# cyt4dn register map
Vendor: Cypress Semiconductor; Series: cyt4dn; File version: 1.0
CPU: CM7 r0p1, little endian, MPU, FPU, VTOR, 3 interrupt priority bits
Registers are 32-bit, read-write, reset 0x0 unless marked. A register's access mark holds for its fields unless they carry their own. Offsets are from the block's base; [hi:lo] are bit positions; lines under a group give offsets from that group; {n}, {i} and the like mark numbered series; 'fields as' and 'values as' point back to an identical list.

## VIDEOSS0 (part 1 of 18) — Video and Graphics Subsystem
Base 0x40A00000
0x00 SUBSS group — Sub Interface
  0x00 VIDEOSSCFG group — Subsystem Control.
    0x00 IPCTRL — IP Control Register
      [31] CTLENABLED — VIDEOSS enable/disable bit.
        0=DIS (Disable the entire VIDEOSS. System will be held in reset until re-enabled (with the exception of the AHB interface and this register)); 1=EN (Enable VIDEOSS)
    0x04 IPCTRLGFX2D reset 0x80000000 — IP Control Register for Graphics 2D Core
      [31] CTLENABLED_GFX2D
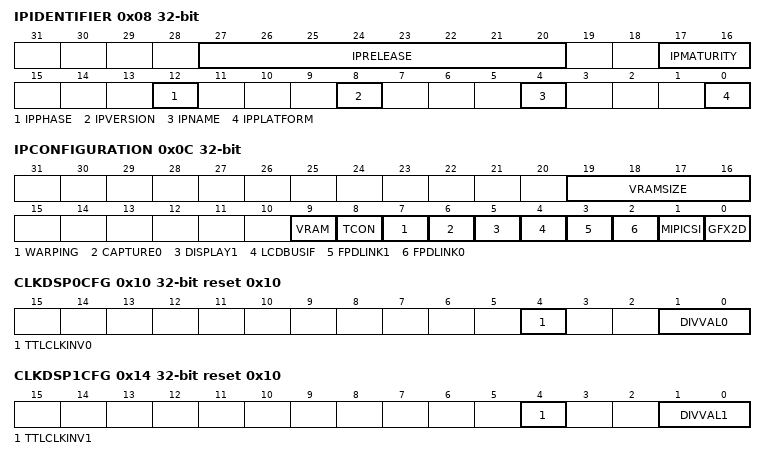
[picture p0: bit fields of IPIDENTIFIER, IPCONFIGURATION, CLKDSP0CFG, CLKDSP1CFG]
    0x08 IPIDENTIFIER ro reset not defined — IP and Design Release Identification
      [27:20] IPRELEASE — Design Release ID
      [17:16] IPMATURITY — CIC Chip Integration Cycle
        0=NONE (Pre Review); 1=CPR (CIC Physical Readiness Review); 2=CMR (CIC Mock Review); 3=CFR (CIC Final Handoff Review)
      [12] IPPHASE — IP Vault Phase
      [8] IPVERSION — IP Vault Version
      [4] IPNAME — Name of IP
        0=VIDEOSS (Video and Graphics Subsystem)
      [0] IPPLATFORM — Name of SOC Platform
        0=MXS40_S40E (MXS40 High Temperature Variant)
    0x0C IPCONFIGURATION ro reset not defined — IP Design Configuration
      [19:16] VRAMSIZE — Size of embedded Video RAM if available (in MB).
      [9] VRAM — Embedded Video RAM available (0 = no, 1 = yes)
      [8] TCON — Timing Controller available in Display Engine (0 = no, 1 = yes)
      [7] WARPING — Warping Layer available in Composition Engine (0 = no, 1 = yes)
      [6] CAPTURE0 — Capture Engine available (0 = no, 1 = yes)
      [5] DISPLAY1 — 2nd Display Engine available (0 = no, 1 = yes)
      [4] LCDBUSIF — LCD Bus Output Interface available (0 = no, 1 = yes)
      [3] FPDLINK1 — 2nd FPD-Link Video Output Interface available (0 = no, 1 = yes)
      [2] FPDLINK0 — 1st FPD-Link Video Output Interface available (0 = no, 1 = yes)
      [1] MIPICSI — MIPI CSI-2 Video Input Interface available (0 = no, 1 = yes)
      [0] GFX2D — Graphics 2D Core available (0 = no, 1 = yes)
    0x10 CLKDSP0CFG reset 0x10 — Display 0 Clock Configuration Register
      [4] TTLCLKINV0 — Enable bit for pixel clock inversion on TTL display output interface 0. If enabled, pixel data changes with falling instead of rising clock edge (180 deg phase shift).
      [1:0] DIVVAL0 — Clock Divider Setting (KDIV)
        0=DIV1 (No division); 1=DIV2 (Divide by 2); 2=DIV4 (Divide by 4); 3=DIV8 (Divide by 8)
    0x14 CLKDSP1CFG reset 0x10 — Display 1 Clock Configuration Register
      [4] TTLCLKINV1 — Enable bit for pixel clock inversion on TTL display output interface 1. If enabled, pixel data changes with falling instead of rising clock edge (180 deg phase shift).
      [1:0] DIVVAL1 — Clock Divider Setting (KDIV)
        values as SUBSS.VIDEOSSCFG.CLKDSP0CFG.DIVVAL0
    0x18 CAP0CFG — Capture 0 Confifuration
      [1:0] CAP0SRC — Capture Source Selection
        0=TTL (TTL0 interface selected); 1=CSI (CSI-2 (DPHY) Interface Selected); 2=DSP0 (N/A); 3=DSP1 (N/A)
    0x1C FPDLINKCFG — FPDLink Configuration
      [0] FPDLINKSEL — Selects the channel mode for the two FDP-link interfaces.
        0=SINGLE (FPD-link 0 and 1 are operating independently, driven by the two Display Engine 0 and 1.); 1=DUAL (FPD-link 0 and 1 are operating synchronously, both driven by Display Engine 0.)
  0x400 VRAM group — Video RAM.
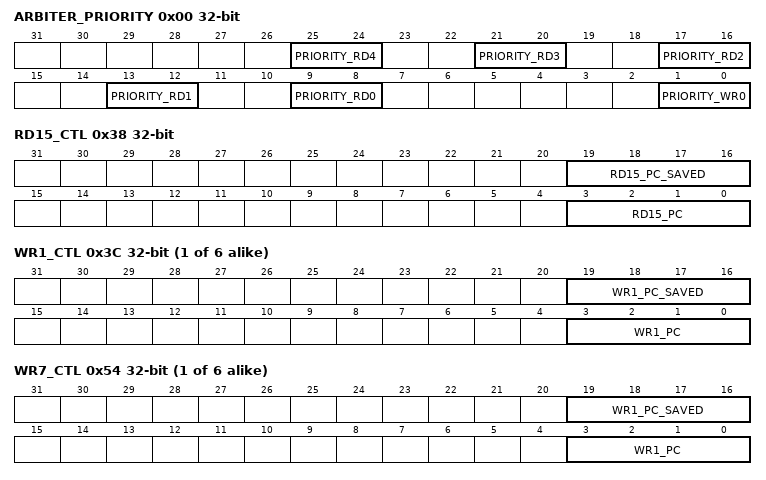
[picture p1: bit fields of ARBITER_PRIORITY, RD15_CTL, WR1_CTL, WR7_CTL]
    0x00 ARBITER_PRIORITY
      [4n+9:4n+8] PRIORITY_RD{n} (n=0..4) — Priority for read slave interface {n}.
      [1:0] PRIORITY_WR0 — Priority for write slave interfaces 0.
  0x10000 INFRA group — Bus Infrastructure.
    0x00 GFX_MPU group — MPU configuration.
      0x00 RD1_CTL — Memory protection context for AXI read master with ID=1
        [19:16] RD1_PC_SAVED — Saved protection context. Modifications to this field are constrained by the associated RDx_CTL.PC_MASK_0 and RDx_CTL.PC_MASK_15_TO_1[] fields.
        [3:0] RD1_PC — Active protection context. Modifications to this field are constrained by the associated RDx_CTL.PC_MASK_0 and RDx_CTL.PC_MASK_15_TO_1[] fields.
      0x04 RD2_CTL — Memory protection context for AXI read master with ID=2
        [19:16] RD2_PC_SAVED — Saved protection context. Modifications to this field are constrained by the associated RDx_CTL.PC_MASK_0 and RDx_CTL.PC_MASK_15_TO_1[] fields.
        [3:0] RD2_PC — Active protection context. Modifications to this field are constrained by the associated RDx_CTL.PC_MASK_0 and RDx_CTL.PC_MASK_15_TO_1[] fields.
      0x08 RD3_CTL — Memory protection context for AXI read master with ID=3
        [19:16] RD3_PC_SAVED — Saved protection context. Modifications to this field are constrained by the associated RDx_CTL.PC_MASK_0 and RDx_CTL.PC_MASK_15_TO_1[] fields.
        [3:0] RD3_PC — Active protection context. Modifications to this field are constrained by the associated RDx_CTL.PC_MASK_0 and RDx_CTL.PC_MASK_15_TO_1[] fields.
      0x0C RD4_CTL — Memory protection context for AXI read master with ID=4
        [19:16] RD4_PC_SAVED — Saved protection context. Modifications to this field are constrained by the associated RDx_CTL.PC_MASK_0 and RDx_CTL.PC_MASK_15_TO_1[] fields.
        [3:0] RD4_PC — Active protection context. Modifications to this field are constrained by the associated RDx_CTL.PC_MASK_0 and RDx_CTL.PC_MASK_15_TO_1[] fields.
      0x10 RD5_CTL — Memory protection context for AXI read master with ID=5
        [19:16] RD5_PC_SAVED — Saved protection context. Modifications to this field are constrained by the associated RDx_CTL.PC_MASK_0 and RDx_CTL.PC_MASK_15_TO_1[] fields.
        [3:0] RD5_PC — Active protection context. Modifications to this field are constrained by the associated RDx_CTL.PC_MASK_0 and RDx_CTL.PC_MASK_15_TO_1[] fields.
      0x14 RD6_CTL — Memory protection context for AXI read master with ID=6
        [19:16] RD6_PC_SAVED — Saved protection context. Modifications to this field are constrained by the associated RDx_CTL.PC_MASK_0 and RDx_CTL.PC_MASK_15_TO_1[] fields.
        [3:0] RD6_PC — Active protection context. Modifications to this field are constrained by the associated RDx_CTL.PC_MASK_0 and RDx_CTL.PC_MASK_15_TO_1[] fields.
      0x18 RD7_CTL — Memory protection7context for AXI read master with ID=7
        [19:16] RD7_PC_SAVED — Saved protection context. Modifications to this field are constrained by the associated RDx_CTL.PC_MASK_0 and RDx_CTL.PC_MASK_15_TO_1[] fields.
        [3:0] RD7_PC — Active protection context. Modifications to this field are constrained by the associated RDx_CTL.PC_MASK_0 and RDx_CTL.PC_MASK_15_TO_1[] fields.
      0x1C RD8_CTL — Memory protection7context for AXI read master with ID=8
        [19:16] RD8_PC_SAVED — Saved protection context. Modifications to this field are constrained by the associated RDx_CTL.PC_MASK_0 and RDx_CTL.PC_MASK_15_TO_1[] fields.
        [3:0] RD8_PC — Active protection context. Modifications to this field are constrained by the associated RDx_CTL.PC_MASK_0 and RDx_CTL.PC_MASK_15_TO_1[] fields.
      0x20 RD9_CTL — Memory protection7context for AXI read master with ID=9
        [19:16] RD9_PC_SAVED — Saved protection context. Modifications to this field are constrained by the associated RDx_CTL.PC_MASK_0 and RDx_CTL.PC_MASK_15_TO_1[] fields.
        [3:0] RD9_PC — Active protection context. Modifications to this field are constrained by the associated RDx_CTL.PC_MASK_0 and RDx_CTL.PC_MASK_15_TO_1[] fields.
      0x24 RD10_CTL — Memory protection7context for AXI read master with ID=10
        [19:16] RD10_PC_SAVED — Saved protection context. Modifications to this field are constrained by the associated RDx_CTL.PC_MASK_0 and RDx_CTL.PC_MASK_15_TO_1[] fields.
        [3:0] RD10_PC — Active protection context. Modifications to this field are constrained by the associated RDx_CTL.PC_MASK_0 and RDx_CTL.PC_MASK_15_TO_1[] fields.
      0x28 RD11_CTL — Memory protection7context for AXI read master with ID=11
        [19:16] RD11_PC_SAVED — Saved protection context. Modifications to this field are constrained by the associated RDx_CTL.PC_MASK_0 and RDx_CTL.PC_MASK_15_TO_1[] fields.
        [3:0] RD11_PC — Active protection context. Modifications to this field are constrained by the associated RDx_CTL.PC_MASK_0 and RDx_CTL.PC_MASK_15_TO_1[] fields.
      0x2C RD12_CTL — Memory protection7context for AXI read master with ID=12
        [19:16] RD12_PC_SAVED — Saved protection context. Modifications to this field are constrained by the associated RDx_CTL.PC_MASK_0 and RDx_CTL.PC_MASK_15_TO_1[] fields.
        [3:0] RD12_PC — Active protection context. Modifications to this field are constrained by the associated RDx_CTL.PC_MASK_0 and RDx_CTL.PC_MASK_15_TO_1[] fields.
      0x30 RD13_CTL — Memory protection7context for AXI read master with ID=12
        [19:16] RD13_PC_SAVED — Saved protection context. Modifications to this field are constrained by the associated RDx_CTL.PC_MASK_0 and RDx_CTL.PC_MASK_15_TO_1[] fields.
        [3:0] RD13_PC — Active protection context. Modifications to this field are constrained by the associated RDx_CTL.PC_MASK_0 and RDx_CTL.PC_MASK_15_TO_1[] fields.
      0x34 RD14_CTL — Memory protection7context for AXI read master with ID=12
        [19:16] RD14_PC_SAVED — Saved protection context. Modifications to this field are constrained by the associated RDx_CTL.PC_MASK_0 and RDx_CTL.PC_MASK_15_TO_1[] fields.
        [3:0] RD14_PC — Active protection context. Modifications to this field are constrained by the associated RDx_CTL.PC_MASK_0 and RDx_CTL.PC_MASK_15_TO_1[] fields.
      0x38 RD15_CTL — Memory protection7context for AXI read master with ID=12
        [19:16] RD15_PC_SAVED — Saved protection context. Modifications to this field are constrained by the associated RDx_CTL.PC_MASK_0 and RDx_CTL.PC_MASK_15_TO_1[] fields.
        [3:0] RD15_PC — Active protection context. Modifications to this field are constrained by the associated RDx_CTL.PC_MASK_0 and RDx_CTL.PC_MASK_15_TO_1[] fields.
      {0x38+4l} WR{l}_CTL (l=1..6) — Memory protection context for AXI write master with ID={l}
        [19:16] WR{l}_PC_SAVED — Saved protection context. Modifications to this field are constrained by the associated WRx_CTL.PC_MASK_0 and WRx_CTL.PC_MASK_15_TO_1[] fields.
        [3:0] WR{l}_PC — Active protection context. Modifications to this field are constrained by the associated WRx_CTL.PC_MASK_0 and WRx_CTL.PC_MASK_15_TO_1[] fields.
      {0x38+4l} WR{l}_CTL (l=7..12) — Memory protection7context for AXI write master with ID={l}
        fields as SUBSS.INFRA.GFX_MPU.WR1_CTL
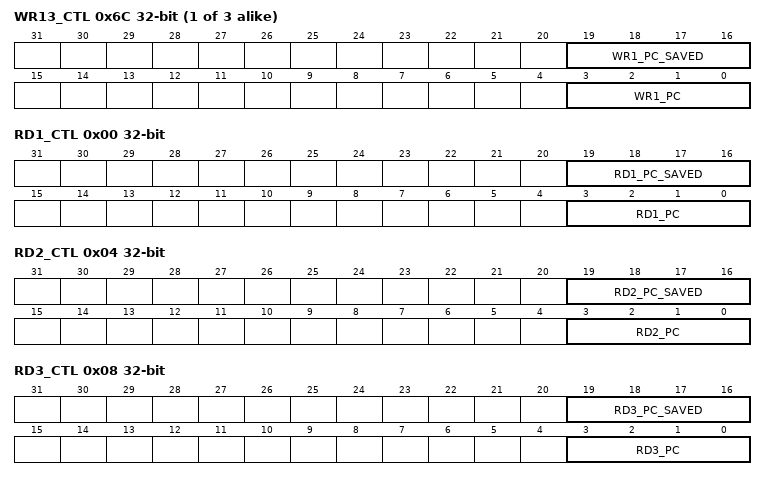
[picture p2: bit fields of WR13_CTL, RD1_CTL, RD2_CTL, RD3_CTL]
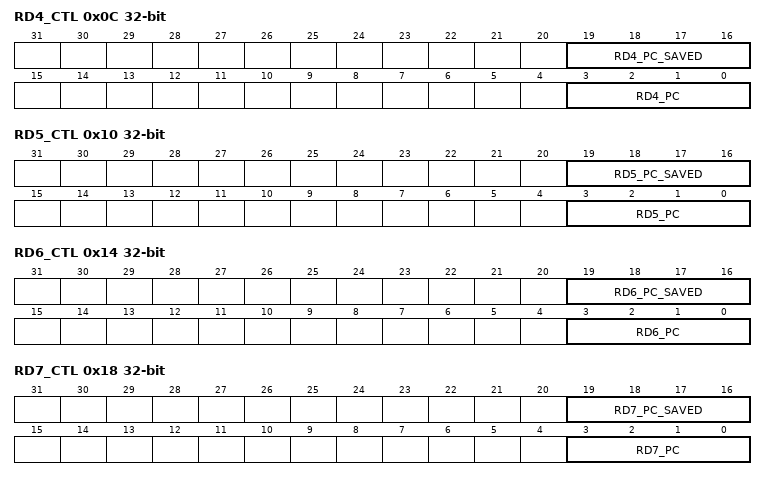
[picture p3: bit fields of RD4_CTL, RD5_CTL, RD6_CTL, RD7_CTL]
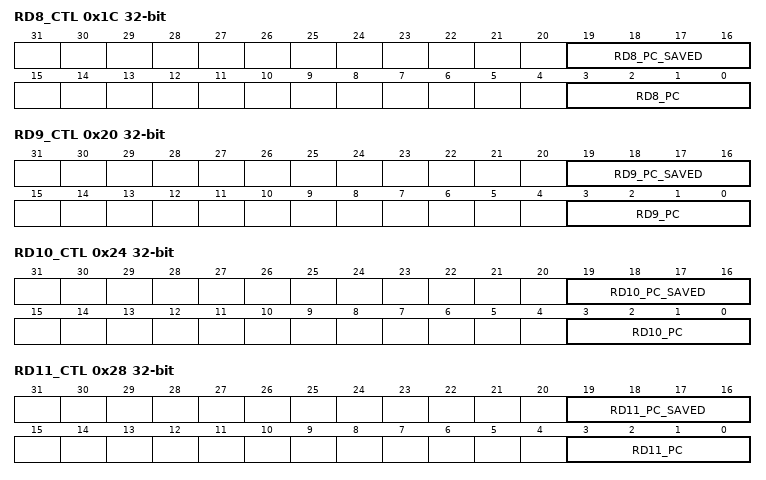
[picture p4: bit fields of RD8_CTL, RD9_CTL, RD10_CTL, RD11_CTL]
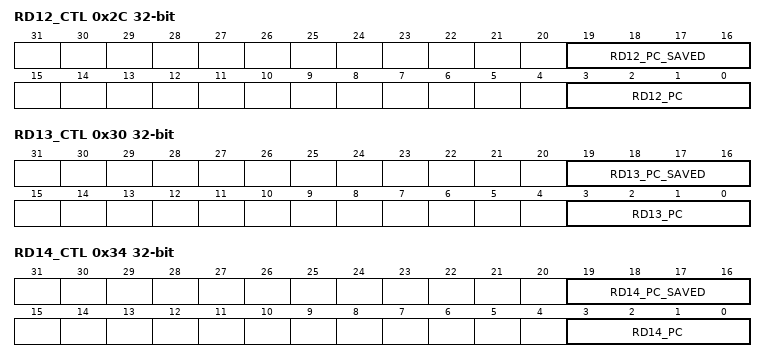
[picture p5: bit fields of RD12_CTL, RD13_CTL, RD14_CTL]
      {0x38+4l} WR{l}_CTL (l=13..15) — Memory protection7context for AXI write master with ID=12
        fields as SUBSS.INFRA.GFX_MPU.WR1_CTL
    0x400 VRPU group — VRPU configuration.
      0x00 RD1_CTL reset 0x303 — VRAM Protection for read master with ID=1
        [31:17] RD1_PC_MASK_15_TO_1 — Protection context mask for protection contexts '15' downto '1'. Bit PC_MASK_15_TO_1[i] indicates if the MPU MS_CTL.PC[3:0] protection context field can be set to the value 'i+1': - PC_MASK_15_TO_1[i] is '0': MPU MS_CTL.PC[3:0] can NOT be set to 'i+1'; and PC[3:0] is not changed. If the protection context of the write transfer is '0', protection is not applied and PC[3:0] can be changed. - PC_MASK_15_TO_1[i] is '1': MPU MS_CTL.PC[3:0] can be set to 'i+1'.
        [16] RD1_PC_MASK_0 ro — Protection context mask for protection context '0'. This field is a constant '0'.
        [9:8] RD1_PRIO — Device wide bus arbitration priority setting ('0': highest priority, '3': lowest priority). Masters with the same priority setting form a 'priority group'. Within a 'priority group', roundrobin arbitration is performed.
        [1] RD1_NS — Security setting ('0': secure mode; '1': non-secure mode).
        [0] RD1_P — Privileged setting ('0': user mode; '1': privileged mode).
      0x04 RD2_CTL reset 0x303 — VRAM Protection for read master with ID=2
        [31:17] RD2_PC_MASK_15_TO_1 — Protection context mask for protection contexts '15' downto '1'. Bit PC_MASK_15_TO_1[i] indicates if the MPU MS_CTL.PC[3:0] protection context field can be set to the value 'i+1': - PC_MASK_15_TO_1[i] is '0': MPU MS_CTL.PC[3:0] can NOT be set to 'i+1'; and PC[3:0] is not changed. If the protection context of the write transfer is '0', protection is not applied and PC[3:0] can be changed. - PC_MASK_15_TO_1[i] is '1': MPU MS_CTL.PC[3:0] can be set to 'i+1'.
        [16] RD2_PC_MASK_0 ro — Protection context mask for protection context '0'. This field is a constant '0'.
        [9:8] RD2_PRIO — Device wide bus arbitration priority setting ('0': highest priority, '3': lowest priority). Masters with the same priority setting form a 'priority group'. Within a 'priority group', roundrobin arbitration is performed.
        [1] RD2_NS — Security setting ('0': secure mode; '1': non-secure mode).
        [0] RD2_P — Privileged setting ('0': user mode; '1': privileged mode).
      0x08 RD3_CTL reset 0x303 — VRAM Protection for read master with ID=3
        [31:17] RD3_PC_MASK_15_TO_1 — Protection context mask for protection contexts '15' downto '1'. Bit PC_MASK_15_TO_1[i] indicates if the MPU MS_CTL.PC[3:0] protection context field can be set to the value 'i+1': - PC_MASK_15_TO_1[i] is '0': MPU MS_CTL.PC[3:0] can NOT be set to 'i+1'; and PC[3:0] is not changed. If the protection context of the write transfer is '0', protection is not applied and PC[3:0] can be changed. - PC_MASK_15_TO_1[i] is '1': MPU MS_CTL.PC[3:0] can be set to 'i+1'.
        [16] RD3_PC_MASK_0 ro — Protection context mask for protection context '0'. This field is a constant '0'.
        [9:8] RD3_PRIO — Device wide bus arbitration priority setting ('0': highest priority, '3': lowest priority). Masters with the same priority setting form a 'priority group'. Within a 'priority group', roundrobin arbitration is performed.
        [1] RD3_NS — Security setting ('0': secure mode; '1': non-secure mode).
        [0] RD3_P — Privileged setting ('0': user mode; '1': privileged mode).
      0x0C RD4_CTL reset 0x303 — VRAM Protection for read master with ID=4
        [31:17] RD4_PC_MASK_15_TO_1 — Protection context mask for protection contexts '15' downto '1'. Bit PC_MASK_15_TO_1[i] indicates if the MPU MS_CTL.PC[3:0] protection context field can be set to the value 'i+1': - PC_MASK_15_TO_1[i] is '0': MPU MS_CTL.PC[3:0] can NOT be set to 'i+1'; and PC[3:0] is not changed. If the protection context of the write transfer is '0', protection is not applied and PC[3:0] can be changed. - PC_MASK_15_TO_1[i] is '1': MPU MS_CTL.PC[3:0] can be set to 'i+1'.
        [16] RD4_PC_MASK_0 ro — Protection context mask for protection context '0'. This field is a constant '0'.
        [9:8] RD4_PRIO — Device wide bus arbitration priority setting ('0': highest priority, '3': lowest priority). Masters with the same priority setting form a 'priority group'. Within a 'priority group', roundrobin arbitration is performed.
        [1] RD4_NS — Security setting ('0': secure mode; '1': non-secure mode).
        [0] RD4_P — Privileged setting ('0': user mode; '1': privileged mode).
      0x10 RD5_CTL reset 0x303 — VRAM Protection for read master with ID=5
        [31:17] RD5_PC_MASK_15_TO_1 — Protection context mask for protection contexts '15' downto '1'. Bit PC_MASK_15_TO_1[i] indicates if the MPU MS_CTL.PC[3:0] protection context field can be set to the value 'i+1': - PC_MASK_15_TO_1[i] is '0': MPU MS_CTL.PC[3:0] can NOT be set to 'i+1'; and PC[3:0] is not changed. If the protection context of the write transfer is '0', protection is not applied and PC[3:0] can be changed. - PC_MASK_15_TO_1[i] is '1': MPU MS_CTL.PC[3:0] can be set to 'i+1'.
        [16] RD5_PC_MASK_0 ro — Protection context mask for protection context '0'. This field is a constant '0'.
        [9:8] RD5_PRIO — Device wide bus arbitration priority setting ('0': highest priority, '3': lowest priority). Masters with the same priority setting form a 'priority group'. Within a 'priority group', roundrobin arbitration is performed.
        [1] RD5_NS — Security setting ('0': secure mode; '1': non-secure mode).
        [0] RD5_P — Privileged setting ('0': user mode; '1': privileged mode).
      0x14 RD6_CTL reset 0x303 — VRAM Protection for read master with ID=6
        [31:17] RD6_PC_MASK_15_TO_1 — Protection context mask for protection contexts '15' downto '1'. Bit PC_MASK_15_TO_1[i] indicates if the MPU MS_CTL.PC[3:0] protection context field can be set to the value 'i+1': - PC_MASK_15_TO_1[i] is '0': MPU MS_CTL.PC[3:0] can NOT be set to 'i+1'; and PC[3:0] is not changed. If the protection context of the write transfer is '0', protection is not applied and PC[3:0] can be changed. - PC_MASK_15_TO_1[i] is '1': MPU MS_CTL.PC[3:0] can be set to 'i+1'.
        [16] RD6_PC_MASK_0 ro — Protection context mask for protection context '0'. This field is a constant '0'.
        [9:8] RD6_PRIO — Device wide bus arbitration priority setting ('0': highest priority, '3': lowest priority). Masters with the same priority setting form a 'priority group'. Within a 'priority group', roundrobin arbitration is performed.
        [1] RD6_NS — Security setting ('0': secure mode; '1': non-secure mode).
        [0] RD6_P — Privileged setting ('0': user mode; '1': privileged mode).
      0x18 RD7_CTL reset 0x303 — VRAM Protection for read master with ID=7
        [31:17] RD7_PC_MASK_15_TO_1 — Protection context mask for protection contexts '15' downto '1'. Bit PC_MASK_15_TO_1[i] indicates if the MPU MS_CTL.PC[3:0] protection context field can be set to the value 'i+1': - PC_MASK_15_TO_1[i] is '0': MPU MS_CTL.PC[3:0] can NOT be set to 'i+1'; and PC[3:0] is not changed. If the protection context of the write transfer is '0', protection is not applied and PC[3:0] can be changed. - PC_MASK_15_TO_1[i] is '1': MPU MS_CTL.PC[3:0] can be set to 'i+1'.
        [16] RD7_PC_MASK_0 ro — Protection context mask for protection context '0'. This field is a constant '0'.
        [9:8] RD7_PRIO — Device wide bus arbitration priority setting ('0': highest priority, '3': lowest priority). Masters with the same priority setting form a 'priority group'. Within a 'priority group', roundrobin arbitration is performed.
        [1] RD7_NS — Security setting ('0': secure mode; '1': non-secure mode).
        [0] RD7_P — Privileged setting ('0': user mode; '1': privileged mode).
      0x1C RD8_CTL reset 0x303 — VRAM Protection for read master with ID=8
        [31:17] RD8_PC_MASK_15_TO_1 — Protection context mask for protection contexts '15' downto '1'. Bit PC_MASK_15_TO_1[i] indicates if the MPU MS_CTL.PC[3:0] protection context field can be set to the value 'i+1': - PC_MASK_15_TO_1[i] is '0': MPU MS_CTL.PC[3:0] can NOT be set to 'i+1'; and PC[3:0] is not changed. If the protection context of the write transfer is '0', protection is not applied and PC[3:0] can be changed. - PC_MASK_15_TO_1[i] is '1': MPU MS_CTL.PC[3:0] can be set to 'i+1'.
        [16] RD8_PC_MASK_0 ro — Protection context mask for protection context '0'. This field is a constant '0'.
        [9:8] RD8_PRIO — Device wide bus arbitration priority setting ('0': highest priority, '3': lowest priority). Masters with the same priority setting form a 'priority group'. Within a 'priority group', roundrobin arbitration is performed.
        [1] RD8_NS — Security setting ('0': secure mode; '1': non-secure mode).
        [0] RD8_P — Privileged setting ('0': user mode; '1': privileged mode).
      0x20 RD9_CTL reset 0x303 — VRAM Protection for read master with ID=9
        [31:17] RD9_PC_MASK_15_TO_1 — Protection context mask for protection contexts '15' downto '1'. Bit PC_MASK_15_TO_1[i] indicates if the MPU MS_CTL.PC[3:0] protection context field can be set to the value 'i+1': - PC_MASK_15_TO_1[i] is '0': MPU MS_CTL.PC[3:0] can NOT be set to 'i+1'; and PC[3:0] is not changed. If the protection context of the write transfer is '0', protection is not applied and PC[3:0] can be changed. - PC_MASK_15_TO_1[i] is '1': MPU MS_CTL.PC[3:0] can be set to 'i+1'.
        [16] RD9_PC_MASK_0 ro — Protection context mask for protection context '0'. This field is a constant '0'.
        [9:8] RD9_PRIO — Device wide bus arbitration priority setting ('0': highest priority, '3': lowest priority). Masters with the same priority setting form a 'priority group'. Within a 'priority group', roundrobin arbitration is performed.
        [1] RD9_NS — Security setting ('0': secure mode; '1': non-secure mode).
        [0] RD9_P — Privileged setting ('0': user mode; '1': privileged mode).
      0x24 RD10_CTL reset 0x303 — VRAM Protection for read master with ID=10
        [31:17] RD10_PC_MASK_15_TO_1 — Protection context mask for protection contexts '15' downto '1'. Bit PC_MASK_15_TO_1[i] indicates if the MPU MS_CTL.PC[3:0] protection context field can be set to the value 'i+1': - PC_MASK_15_TO_1[i] is '0': MPU MS_CTL.PC[3:0] can NOT be set to 'i+1'; and PC[3:0] is not changed. If the protection context of the write transfer is '0', protection is not applied and PC[3:0] can be changed. - PC_MASK_15_TO_1[i] is '1': MPU MS_CTL.PC[3:0] can be set to 'i+1'.
        [16] RD10_PC_MASK_0 ro — Protection context mask for protection context '0'. This field is a constant '0'.
        [9:8] RD10_PRIO — Device wide bus arbitration priority setting ('0': highest priority, '3': lowest priority). Masters with the same priority setting form a 'priority group'. Within a 'priority group', roundrobin arbitration is performed.
        [1] RD10_NS — Security setting ('0': secure mode; '1': non-secure mode).
        [0] RD10_P — Privileged setting ('0': user mode; '1': privileged mode).
      0x28 RD11_CTL reset 0x303 — VRAM Protection for read master with ID=11
        [31:17] RD11_PC_MASK_15_TO_1 — Protection context mask for protection contexts '15' downto '1'. Bit PC_MASK_15_TO_1[i] indicates if the MPU MS_CTL.PC[3:0] protection context field can be set to the value 'i+1': - PC_MASK_15_TO_1[i] is '0': MPU MS_CTL.PC[3:0] can NOT be set to 'i+1'; and PC[3:0] is not changed. If the protection context of the write transfer is '0', protection is not applied and PC[3:0] can be changed. - PC_MASK_15_TO_1[i] is '1': MPU MS_CTL.PC[3:0] can be set to 'i+1'.
        [16] RD11_PC_MASK_0 ro — Protection context mask for protection context '0'. This field is a constant '0'.
        [9:8] RD11_PRIO — Device wide bus arbitration priority setting ('0': highest priority, '3': lowest priority). Masters with the same priority setting form a 'priority group'. Within a 'priority group', roundrobin arbitration is performed.
        [1] RD11_NS — Security setting ('0': secure mode; '1': non-secure mode).
        [0] RD11_P — Privileged setting ('0': user mode; '1': privileged mode).
      0x2C RD12_CTL reset 0x303 — VRAM Protection for read master with ID=12
        [31:17] RD12_PC_MASK_15_TO_1 — Protection context mask for protection contexts '15' downto '1'. Bit PC_MASK_15_TO_1[i] indicates if the MPU MS_CTL.PC[3:0] protection context field can be set to the value 'i+1': - PC_MASK_15_TO_1[i] is '0': MPU MS_CTL.PC[3:0] can NOT be set to 'i+1'; and PC[3:0] is not changed. If the protection context of the write transfer is '0', protection is not applied and PC[3:0] can be changed. - PC_MASK_15_TO_1[i] is '1': MPU MS_CTL.PC[3:0] can be set to 'i+1'.
        [16] RD12_PC_MASK_0 ro — Protection context mask for protection context '0'. This field is a constant '0'.
        [9:8] RD12_PRIO — Device wide bus arbitration priority setting ('0': highest priority, '3': lowest priority). Masters with the same priority setting form a 'priority group'. Within a 'priority group', roundrobin arbitration is performed.
        [1] RD12_NS — Security setting ('0': secure mode; '1': non-secure mode).
        [0] RD12_P — Privileged setting ('0': user mode; '1': privileged mode).
      0x30 RD13_CTL reset 0x303 — VRAM Protection for read master with ID=13
        [31:17] RD13_PC_MASK_15_TO_1 — Protection context mask for protection contexts '15' downto '1'. Bit PC_MASK_15_TO_1[i] indicates if the MPU MS_CTL.PC[3:0] protection context field can be set to the value 'i+1': - PC_MASK_15_TO_1[i] is '0': MPU MS_CTL.PC[3:0] can NOT be set to 'i+1'; and PC[3:0] is not changed. If the protection context of the write transfer is '0', protection is not applied and PC[3:0] can be changed. - PC_MASK_15_TO_1[i] is '1': MPU MS_CTL.PC[3:0] can be set to 'i+1'.
        [16] RD13_PC_MASK_0 ro — Protection context mask for protection context '0'. This field is a constant '0'.
        [9:8] RD13_PRIO — Device wide bus arbitration priority setting ('0': highest priority, '3': lowest priority). Masters with the same priority setting form a 'priority group'. Within a 'priority group', roundrobin arbitration is performed.
        [1] RD13_NS — Security setting ('0': secure mode; '1': non-secure mode).
        [0] RD13_P — Privileged setting ('0': user mode; '1': privileged mode).
      0x34 RD14_CTL reset 0x303 — VRAM Protection for read master with ID=14
        [31:17] RD14_PC_MASK_15_TO_1 — Protection context mask for protection contexts '15' downto '1'. Bit PC_MASK_15_TO_1[i] indicates if the MPU MS_CTL.PC[3:0] protection context field can be set to the value 'i+1': - PC_MASK_15_TO_1[i] is '0': MPU MS_CTL.PC[3:0] can NOT be set to 'i+1'; and PC[3:0] is not changed. If the protection context of the write transfer is '0', protection is not applied and PC[3:0] can be changed. - PC_MASK_15_TO_1[i] is '1': MPU MS_CTL.PC[3:0] can be set to 'i+1'.
        [16] RD14_PC_MASK_0 ro — Protection context mask for protection context '0'. This field is a constant '0'.
        [9:8] RD14_PRIO — Device wide bus arbitration priority setting ('0': highest priority, '3': lowest priority). Masters with the same priority setting form a 'priority group'. Within a 'priority group', roundrobin arbitration is performed.
        [1] RD14_NS — Security setting ('0': secure mode; '1': non-secure mode).
        [0] RD14_P — Privileged setting ('0': user mode; '1': privileged mode).
